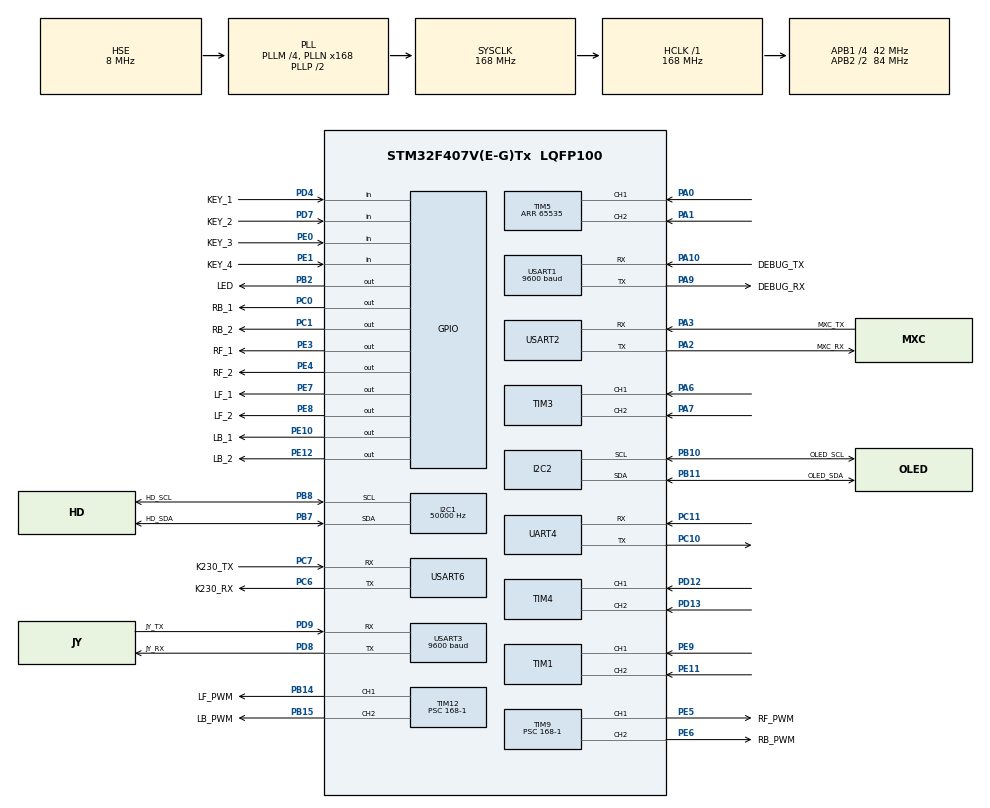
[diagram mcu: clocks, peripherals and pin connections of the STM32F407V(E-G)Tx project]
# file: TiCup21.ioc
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Dma.Request0=USART1_RX
Dma.Request1=USART1_TX
Dma.Request2=UART4_RX
Dma.Request3=UART4_TX
Dma.UART4_RX.2.Direction=DMA_PERIPH_TO_MEMORY
Dma.UART4_RX.2.FIFOMode=DMA_FIFOMODE_DISABLE
Dma.UART4_RX.2.Instance=DMA1_Stream2
Dma.UART4_RX.2.MemDataAlignment=DMA_MDATAALIGN_BYTE
Dma.UART4_RX.2.MemInc=DMA_MINC_ENABLE
Dma.UART4_RX.2.Mode=DMA_NORMAL
Dma.UART4_RX.2.PeriphDataAlignment=DMA_PDATAALIGN_BYTE
Dma.UART4_RX.2.PeriphInc=DMA_PINC_DISABLE
Dma.UART4_RX.2.Priority=DMA_PRIORITY_LOW
Dma.UART4_TX.3.Direction=DMA_MEMORY_TO_PERIPH
Dma.UART4_TX.3.FIFOMode=DMA_FIFOMODE_DISABLE
Dma.UART4_TX.3.Instance=DMA1_Stream4
Dma.UART4_TX.3.MemDataAlignment=DMA_MDATAALIGN_BYTE
Dma.UART4_TX.3.MemInc=DMA_MINC_ENABLE
Dma.UART4_TX.3.Mode=DMA_NORMAL
Dma.UART4_TX.3.PeriphDataAlignment=DMA_PDATAALIGN_BYTE
Dma.UART4_TX.3.PeriphInc=DMA_PINC_DISABLE
Dma.UART4_TX.3.Priority=DMA_PRIORITY_LOW
Dma.USART1_RX.0.Direction=DMA_PERIPH_TO_MEMORY
Dma.USART1_RX.0.FIFOMode=DMA_FIFOMODE_DISABLE
Dma.USART1_RX.0.Instance=DMA2_Stream2
Dma.USART1_RX.0.MemDataAlignment=DMA_MDATAALIGN_BYTE
Dma.USART1_RX.0.MemInc=DMA_MINC_ENABLE
Dma.USART1_RX.0.Mode=DMA_NORMAL
Dma.USART1_RX.0.PeriphDataAlignment=DMA_PDATAALIGN_BYTE
Dma.USART1_RX.0.PeriphInc=DMA_PINC_DISABLE
Dma.USART1_RX.0.Priority=DMA_PRIORITY_LOW
Dma.USART1_TX.1.Direction=DMA_MEMORY_TO_PERIPH
Dma.USART1_TX.1.FIFOMode=DMA_FIFOMODE_DISABLE
Dma.USART1_TX.1.Instance=DMA2_Stream7
Dma.USART1_TX.1.MemDataAlignment=DMA_MDATAALIGN_BYTE
Dma.USART1_TX.1.MemInc=DMA_MINC_ENABLE
Dma.USART1_TX.1.Mode=DMA_NORMAL
Dma.USART1_TX.1.PeriphDataAlignment=DMA_PDATAALIGN_BYTE
Dma.USART1_TX.1.PeriphInc=DMA_PINC_DISABLE
Dma.USART1_TX.1.Priority=DMA_PRIORITY_LOW
FREERTOS.Tasks01=defaultTask,24,128,StartDefaultTask,Default,NULL,Dynamic,NULL,NULL
I2C1.ClockSpeed=50000
Mcu.Family=STM32F4
Mcu.Name=STM32F407V(E-G)Tx
Mcu.Package=LQFP100
NVIC.DMA1_Stream2_IRQn=true\:5\:0\:false\:false\:true\:true\:false\:true\:true
NVIC.DMA1_Stream4_IRQn=true\:5\:0\:false\:false\:true\:true\:false\:true\:true
NVIC.DMA2_Stream2_IRQn=true\:5\:0\:false\:false\:true\:true\:false\:true\:true
NVIC.DMA2_Stream7_IRQn=true\:5\:0\:false\:false\:true\:true\:false\:true\:true
NVIC.PriorityGroup=NVIC_PRIORITYGROUP_4
NVIC.TIM6_DAC_IRQn=true\:5\:0\:false\:false\:true\:true\:true\:true\:true
NVIC.TIM7_IRQn=true\:15\:0\:false\:false\:true\:false\:false\:true\:true
NVIC.TimeBase=TIM7_IRQn
NVIC.TimeBaseIP=TIM7
NVIC.UART4_IRQn=true\:5\:0\:false\:false\:true\:true\:true\:true\:true
NVIC.USART1_IRQn=true\:5\:0\:false\:false\:true\:true\:true\:true\:true
NVIC.USART2_IRQn=true\:5\:0\:false\:false\:true\:true\:true\:true\:true
NVIC.USART3_IRQn=true\:5\:0\:false\:false\:true\:true\:true\:true\:true
NVIC.USART6_IRQn=true\:5\:0\:false\:false\:true\:true\:true\:true\:true
PA0-WKUP.Signal=S_TIM5_CH1
PA1.Signal=S_TIM5_CH2
PA10.GPIO_Label=DEBUG_TX
PA10.Mode=Asynchronous
PA10.Signal=USART1_RX
PA13.Mode=Serial_Wire
PA13.Signal=SYS_JTMS-SWDIO
PA14.Mode=Serial_Wire
PA14.Signal=SYS_JTCK-SWCLK
PA2.GPIO_Label=MXC_RX
PA2.Mode=Asynchronous
PA2.Signal=USART2_TX
PA3.GPIO_Label=MXC_TX
PA3.Mode=Asynchronous
PA3.Signal=USART2_RX
PA6.Signal=S_TIM3_CH1
PA7.Signal=S_TIM3_CH2
PA9.GPIO_Label=DEBUG_RX
PA9.Mode=Asynchronous
PA9.Signal=USART1_TX
PB10.GPIO_Label=OLED_SCL
PB10.Mode=I2C
PB10.Signal=I2C2_SCL
PB11.GPIO_Label=OLED_SDA
PB11.Mode=I2C
PB11.Signal=I2C2_SDA
PB14.GPIO_Label=LF_PWM
PB14.Signal=S_TIM12_CH1
PB15.GPIO_Label=LB_PWM
PB15.Signal=S_TIM12_CH2
PB2.GPIO_Label=LED
PB2.Signal=GPIO_Output
PB7.GPIO_Label=HD_SDA
PB7.Mode=I2C
PB7.Signal=I2C1_SDA
PB8.GPIO_Label=HD_SCL
PB8.Mode=I2C
PB8.Signal=I2C1_SCL
PC0.GPIO_Label=RB_1
PC0.GPIO_ModeDefaultOutputPP=GPIO_MODE_OUTPUT_PP
PC0.GPIO_PuPd=GPIO_NOPULL
PC0.PinState=GPIO_PIN_SET
PC0.Signal=GPIO_Output
PC1.GPIO_Label=RB_2
PC1.GPIO_ModeDefaultOutputPP=GPIO_MODE_OUTPUT_PP
PC1.GPIO_PuPd=GPIO_NOPULL
PC1.PinState=GPIO_PIN_SET
PC1.Signal=GPIO_Output
PC10.Mode=Asynchronous
PC10.Signal=UART4_TX
PC11.Mode=Asynchronous
PC11.Signal=UART4_RX
PC14-OSC32_IN.Mode=LSE-External-Oscillator
PC14-OSC32_IN.Signal=RCC_OSC32_IN
PC15-OSC32_OUT.Mode=LSE-External-Oscillator
PC15-OSC32_OUT.Signal=RCC_OSC32_OUT
PC6.GPIO_Label=K230_RX
PC6.Mode=Asynchronous
PC6.Signal=USART6_TX
PC7.GPIO_Label=K230_TX
PC7.Mode=Asynchronous
PC7.Signal=USART6_RX
PD12.Signal=S_TIM4_CH1
PD13.Signal=S_TIM4_CH2
PD4.GPIO_Label=KEY_1
PD4.GPIO_Mode=GPIO_MODE_INPUT
PD4.GPIO_PuPd=GPIO_PULLUP
PD4.Signal=GPIO_Input
PD7.GPIO_Label=KEY_2
PD7.GPIO_Mode=GPIO_MODE_INPUT
PD7.GPIO_PuPd=GPIO_PULLUP
PD7.Signal=GPIO_Input
PD8.GPIO_Label=JY_RX
PD8.Mode=Asynchronous
PD8.Signal=USART3_TX
PD9.GPIO_Label=JY_TX
PD9.Mode=Asynchronous
PD9.Signal=USART3_RX
PE0.GPIO_Label=KEY_3
PE0.GPIO_Mode=GPIO_MODE_INPUT
PE0.GPIO_PuPd=GPIO_PULLUP
PE0.Signal=GPIO_Input
PE1.GPIO_Label=KEY_4
PE1.GPIO_Mode=GPIO_MODE_INPUT
PE1.GPIO_PuPd=GPIO_PULLUP
PE1.Signal=GPIO_Input
PE10.GPIO_Label=LB_1
PE10.GPIO_ModeDefaultOutputPP=GPIO_MODE_OUTPUT_PP
PE10.GPIO_PuPd=GPIO_NOPULL
PE10.PinState=GPIO_PIN_SET
PE10.Signal=GPIO_Output
PE11.Signal=S_TIM1_CH2
PE12.GPIO_Label=LB_2
PE12.GPIO_ModeDefaultOutputPP=GPIO_MODE_OUTPUT_PP
PE12.GPIO_PuPd=GPIO_NOPULL
PE12.PinState=GPIO_PIN_SET
PE12.Signal=GPIO_Output
PE3.GPIO_Label=RF_1
PE3.GPIO_ModeDefaultOutputPP=GPIO_MODE_OUTPUT_PP
PE3.GPIO_PuPd=GPIO_NOPULL
PE3.PinState=GPIO_PIN_SET
PE3.Signal=GPIO_Output
PE4.GPIO_Label=RF_2
PE4.GPIO_ModeDefaultOutputPP=GPIO_MODE_OUTPUT_PP
PE4.GPIO_PuPd=GPIO_NOPULL
PE4.PinState=GPIO_PIN_SET
PE4.Signal=GPIO_Output
PE5.GPIO_Label=RF_PWM
PE5.Signal=S_TIM9_CH1
PE6.GPIO_Label=RB_PWM
PE6.Signal=S_TIM9_CH2
PE7.GPIO_Label=LF_1
PE7.GPIO_ModeDefaultOutputPP=GPIO_MODE_OUTPUT_PP
PE7.GPIO_PuPd=GPIO_NOPULL
PE7.PinState=GPIO_PIN_SET
PE7.Signal=GPIO_Output
PE8.GPIO_Label=LF_2
PE8.GPIO_ModeDefaultOutputPP=GPIO_MODE_OUTPUT_PP
PE8.GPIO_PuPd=GPIO_NOPULL
PE8.PinState=GPIO_PIN_SET
PE8.Signal=GPIO_Output
PE9.Signal=S_TIM1_CH1
PH0-OSC_IN.Mode=HSE-External-Oscillator
PH0-OSC_IN.Signal=RCC_OSC_IN
PH1-OSC_OUT.Mode=HSE-External-Oscillator
PH1-OSC_OUT.Signal=RCC_OSC_OUT
ProjectManager.HeapSize=0x200
ProjectManager.StackSize=0x400
ProjectManager.TargetToolchain=MDK-ARM V5.32
RCC.48MHZClocksFreq_Value=84000000
RCC.AHBFreq_Value=168000000
RCC.APB1CLKDivider=RCC_HCLK_DIV4
RCC.APB1Freq_Value=42000000
RCC.APB1TimFreq_Value=84000000
RCC.APB2CLKDivider=RCC_HCLK_DIV2
RCC.APB2Freq_Value=84000000
RCC.APB2TimFreq_Value=168000000
RCC.CortexFreq_Value=168000000
RCC.HCLKFreq_Value=168000000
RCC.HSE_VALUE=8000000
RCC.HSI_VALUE=16000000
RCC.PLLM=4
RCC.PLLN=168
RCC.PLLSourceVirtual=RCC_PLLSOURCE_HSE
RCC.SYSCLKFreq_VALUE=168000000
RCC.SYSCLKSource=RCC_SYSCLKSOURCE_PLLCLK
RCC.VCOOutputFreq_Value=336000000
SH.S_TIM12_CH1.0=TIM12_CH1,PWM Generation1 CH1
SH.S_TIM12_CH2.0=TIM12_CH2,PWM Generation2 CH2
SH.S_TIM1_CH1.0=TIM1_CH1,Encoder_Interface
SH.S_TIM1_CH2.0=TIM1_CH2,Encoder_Interface
SH.S_TIM3_CH1.0=TIM3_CH1,Encoder_Interface
SH.S_TIM3_CH2.0=TIM3_CH2,Encoder_Interface
SH.S_TIM4_CH1.0=TIM4_CH1,Encoder_Interface
SH.S_TIM4_CH2.0=TIM4_CH2,Encoder_Interface
SH.S_TIM5_CH1.0=TIM5_CH1,Encoder_Interface
SH.S_TIM5_CH2.0=TIM5_CH2,Encoder_Interface
SH.S_TIM9_CH1.0=TIM9_CH1,PWM Generation1 CH1
SH.S_TIM9_CH2.0=TIM9_CH2,PWM Generation2 CH2
TIM1.EncoderMode=TIM_ENCODERMODE_TI12
TIM1.IC1Filter=15
TIM1.IC2Filter=15
TIM12.Channel-PWM\ Generation1\ CH1=TIM_CHANNEL_1
TIM12.Channel-PWM\ Generation2\ CH2=TIM_CHANNEL_2
TIM12.Period=100-1
TIM12.Prescaler=168-1
TIM3.EncoderMode=TIM_ENCODERMODE_TI12
TIM3.IC1Filter=15
TIM3.IC2Filter=15
TIM4.EncoderMode=TIM_ENCODERMODE_TI12
TIM4.IC1Filter=15
TIM4.IC1Polarity=TIM_ICPOLARITY_RISING
TIM4.IC2Filter=15
TIM4.IC2Polarity=TIM_ICPOLARITY_FALLING
TIM5.EncoderMode=TIM_ENCODERMODE_TI12
TIM5.IC1Filter=15
TIM5.IC2Filter=15
TIM5.Period=65535
TIM6.Period=1000-1
TIM6.Prescaler=168-1
TIM9.Channel-PWM\ Generation1\ CH1=TIM_CHANNEL_1
TIM9.Channel-PWM\ Generation2\ CH2=TIM_CHANNEL_2
TIM9.Period=100-1
TIM9.Prescaler=168-1
UART4.VirtualMode=Asynchronous
USART1.BaudRate=9600
USART1.VirtualMode=VM_ASYNC
USART2.VirtualMode=VM_ASYNC
USART3.BaudRate=9600
USART3.VirtualMode=VM_ASYNC
USART6.VirtualMode=VM_ASYNC
VP_FREERTOS_VS_CMSIS_V2.Mode=CMSIS_V2
VP_SYS_VS_tim7.Mode=TIM7
VP_TIM12_VS_ClockSourceINT.Mode=Internal
VP_TIM6_VS_ClockSourceINT.Mode=Enable_Timer
VP_TIM9_VS_ClockSourceINT.Mode=Internal
board=custom

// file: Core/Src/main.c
/* USER CODE BEGIN Header */
/**
  ******************************************************************************
  * @file           : main.c
  * @brief          : Main program body
  ******************************************************************************
  * @attention
  *
  * Copyright (c) 2025 STMicroelectronics.
  * All rights reserved.
  *
  * This software is licensed under terms that can be found in the LICENSE file
  * in the root directory of this software component.
  * If no LICENSE file comes with this software, it is provided AS-IS.
  *
  ******************************************************************************
  */
/* USER CODE END Header */
#include "main.h"
#include "cmsis_os.h"
#include "dma.h"
#include "i2c.h"
#include "tim.h"
#include "usart.h"
#include "gpio.h"

/* USER CODE BEGIN Includes */
#include "my_task.h"
/* USER CODE END Includes */

void SystemClock_Config(void);
void MX_FREERTOS_Init(void);

int main(void)
{

  /* MCU Configuration--------------------------------------------------------*/

  /* Reset of all peripherals, Initializes the Flash interface and the Systick. */
  HAL_Init();

  /* Configure the system clock */
  SystemClock_Config();

  /* Initialize all configured peripherals */
  MX_GPIO_Init();
  MX_DMA_Init();
  MX_I2C1_Init();
  MX_TIM1_Init();
  MX_TIM3_Init();
  MX_TIM4_Init();
  MX_TIM5_Init();
  MX_TIM9_Init();
  MX_TIM12_Init();
  MX_TIM6_Init();
  MX_USART3_UART_Init();
  MX_I2C2_Init();
  MX_USART2_UART_Init();
  MX_USART1_UART_Init();
  MX_USART6_UART_Init();
  MX_UART4_Init();
  /* USER CODE BEGIN 2 */
    MyTask_Init();
  /* USER CODE END 2 */

  /* Init scheduler */
  osKernelInitialize();

  /* Call init function for freertos objects (in cmsis_os2.c) */
  MX_FREERTOS_Init();

  /* Start scheduler */
  osKernelStart();

  /* We should never get here as control is now taken by the scheduler */

  /* Infinite loop */
  while (1)
  {

  }
}

void SystemClock_Config(void)
{
  RCC_OscInitTypeDef RCC_OscInitStruct = {0};
  RCC_ClkInitTypeDef RCC_ClkInitStruct = {0};

  /** Configure the main internal regulator output voltage
  */
  __HAL_RCC_PWR_CLK_ENABLE();
  __HAL_PWR_VOLTAGESCALING_CONFIG(PWR_REGULATOR_VOLTAGE_SCALE1);

  /** Initializes the RCC Oscillators according to the specified parameters
  * in the RCC_OscInitTypeDef structure.
  */
  RCC_OscInitStruct.OscillatorType = RCC_OSCILLATORTYPE_HSE;
  RCC_OscInitStruct.HSEState = RCC_HSE_ON;
  RCC_OscInitStruct.PLL.PLLState = RCC_PLL_ON;
  RCC_OscInitStruct.PLL.PLLSource = RCC_PLLSOURCE_HSE;
  RCC_OscInitStruct.PLL.PLLM = 4;
  RCC_OscInitStruct.PLL.PLLN = 168;
  RCC_OscInitStruct.PLL.PLLP = RCC_PLLP_DIV2;
  RCC_OscInitStruct.PLL.PLLQ = 4;
  if (HAL_RCC_OscConfig(&RCC_OscInitStruct) != HAL_OK)
  {
    Error_Handler();
  }

  /** Initializes the CPU, AHB and APB buses clocks
  */
  RCC_ClkInitStruct.ClockType = RCC_CLOCKTYPE_HCLK|RCC_CLOCKTYPE_SYSCLK
                              |RCC_CLOCKTYPE_PCLK1|RCC_CLOCKTYPE_PCLK2;
  RCC_ClkInitStruct.SYSCLKSource = RCC_SYSCLKSOURCE_PLLCLK;
  RCC_ClkInitStruct.AHBCLKDivider = RCC_SYSCLK_DIV1;
  RCC_ClkInitStruct.APB1CLKDivider = RCC_HCLK_DIV4;
  RCC_ClkInitStruct.APB2CLKDivider = RCC_HCLK_DIV2;

  if (HAL_RCC_ClockConfig(&RCC_ClkInitStruct, FLASH_LATENCY_5) != HAL_OK)
  {
    Error_Handler();
  }
}

void HAL_TIM_PeriodElapsedCallback(TIM_HandleTypeDef *htim)
{
  if (htim->Instance == TIM7) {
    HAL_IncTick();
  }
}

void Error_Handler(void)
{
  __disable_irq();
  while (1)
  {
  }
}
